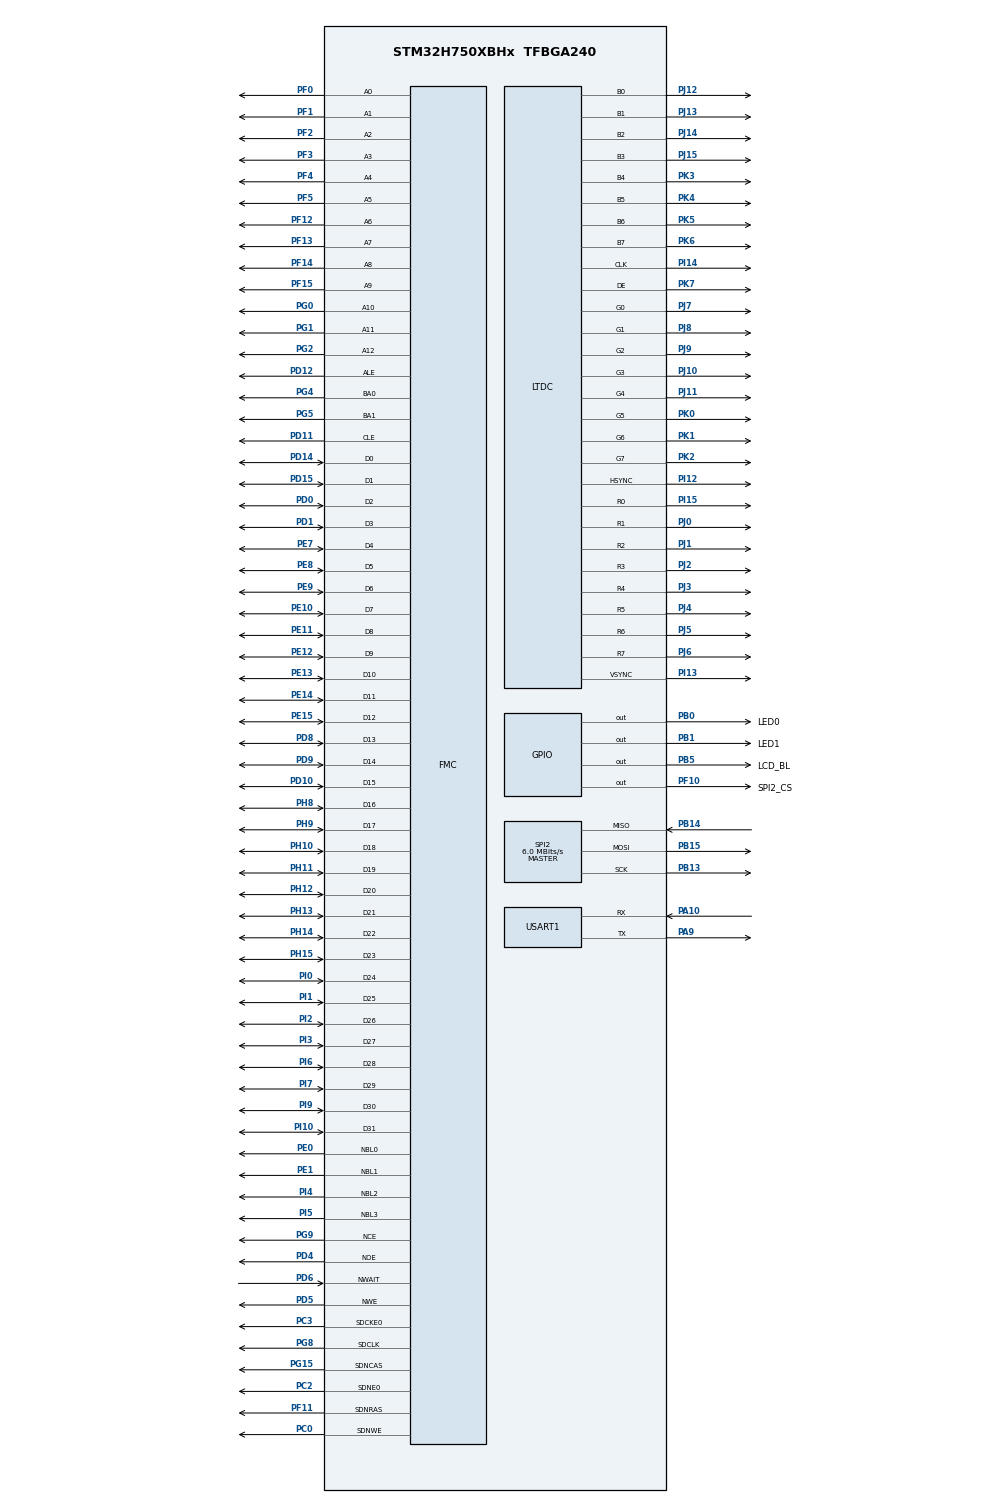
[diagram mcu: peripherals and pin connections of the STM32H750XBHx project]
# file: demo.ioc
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CORTEX_M7.CPU_DCache=Enabled
CORTEX_M7.CPU_ICache=Enabled
Dma.Request0=USART1_RX
Dma.Request1=USART1_TX
Dma.USART1_RX.0.Direction=DMA_PERIPH_TO_MEMORY
Dma.USART1_RX.0.EventEnable=DISABLE
Dma.USART1_RX.0.FIFOMode=DMA_FIFOMODE_DISABLE
Dma.USART1_RX.0.Instance=DMA1_Stream0
Dma.USART1_RX.0.MemDataAlignment=DMA_MDATAALIGN_BYTE
Dma.USART1_RX.0.MemInc=DMA_MINC_ENABLE
Dma.USART1_RX.0.Mode=DMA_CIRCULAR
Dma.USART1_RX.0.PeriphDataAlignment=DMA_PDATAALIGN_BYTE
Dma.USART1_RX.0.PeriphInc=DMA_PINC_DISABLE
Dma.USART1_RX.0.Polarity=HAL_DMAMUX_REQ_GEN_RISING
Dma.USART1_RX.0.Priority=DMA_PRIORITY_HIGH
Dma.USART1_RX.0.RequestNumber=1
Dma.USART1_RX.0.SignalID=NONE
Dma.USART1_RX.0.SyncEnable=DISABLE
Dma.USART1_RX.0.SyncPolarity=HAL_DMAMUX_SYNC_NO_EVENT
Dma.USART1_RX.0.SyncRequestNumber=1
Dma.USART1_RX.0.SyncSignalID=NONE
Dma.USART1_TX.1.Direction=DMA_MEMORY_TO_PERIPH
Dma.USART1_TX.1.EventEnable=DISABLE
Dma.USART1_TX.1.FIFOMode=DMA_FIFOMODE_DISABLE
Dma.USART1_TX.1.Instance=DMA1_Stream1
Dma.USART1_TX.1.MemDataAlignment=DMA_MDATAALIGN_BYTE
Dma.USART1_TX.1.MemInc=DMA_MINC_ENABLE
Dma.USART1_TX.1.Mode=DMA_CIRCULAR
Dma.USART1_TX.1.PeriphDataAlignment=DMA_PDATAALIGN_BYTE
Dma.USART1_TX.1.PeriphInc=DMA_PINC_DISABLE
Dma.USART1_TX.1.Polarity=HAL_DMAMUX_REQ_GEN_RISING
Dma.USART1_TX.1.Priority=DMA_PRIORITY_HIGH
Dma.USART1_TX.1.RequestNumber=1
Dma.USART1_TX.1.SignalID=NONE
Dma.USART1_TX.1.SyncEnable=DISABLE
Dma.USART1_TX.1.SyncPolarity=HAL_DMAMUX_SYNC_NO_EVENT
Dma.USART1_TX.1.SyncRequestNumber=1
Dma.USART1_TX.1.SyncSignalID=NONE
FMC.AttributeSpaceHiZSetupTime1=10
FMC.AttributeSpaceHoldSetupTime1=10
FMC.AttributeSpaceSetupTime1=10
FMC.AttributeSpaceWaitSetupTime1=10
FMC.CASLatency1=FMC_SDRAM_CAS_LATENCY_2
FMC.ColumnBitsNumber1=FMC_SDRAM_COLUMN_BITS_NUM_9
FMC.CommonSpaceHiZSetupTime1=10
FMC.CommonSpaceHoldSetupTime1=10
FMC.CommonSpaceSetupTime1=10
FMC.CommonSpaceWaitSetupTime1=10
FMC.ECCPageSize1=FMC_NAND_ECC_PAGE_SIZE_512BYTE
FMC.ExitSelfRefreshDelay1=8
FMC.LoadToActiveDelay1=2
FMC.NandPageSize1=0
FMC.RCDDelay1=2
FMC.RPDelay1=2
FMC.ReadBurst1=FMC_SDRAM_RBURST_ENABLE
FMC.RowCycleDelay1=6
FMC.SDClockPeriod1=FMC_SDRAM_CLOCK_PERIOD_2
FMC.SelfRefreshTime1=6
FMC.TARSetupTime1=10
FMC.TCLRSetupTime1=10
FMC.WriteRecoveryTime1=4
LTDC.ActiveH=1024
LTDC.ActiveW=600
Mcu.Family=STM32H7
Mcu.Name=STM32H750XBHx
Mcu.Package=TFBGA240
NVIC.DMA1_Stream0_IRQn=true\:0\:0\:false\:false\:true\:false\:true\:true
NVIC.DMA1_Stream1_IRQn=true\:0\:0\:false\:false\:true\:false\:true\:true
NVIC.FMC_IRQn=true\:0\:0\:false\:false\:true\:true\:true\:true
NVIC.PriorityGroup=NVIC_PRIORITYGROUP_4
PA10.Mode=Asynchronous
PA10.Signal=USART1_RX
PA13\ (JTMS/SWDIO).Mode=Serial_Wire
PA13\ (JTMS/SWDIO).Signal=DEBUG_JTMS-SWDIO
PA14\ (JTCK/SWCLK).Mode=Serial_Wire
PA14\ (JTCK/SWCLK).Signal=DEBUG_JTCK-SWCLK
PA9.Mode=Asynchronous
PA9.Signal=USART1_TX
PB0.GPIO_Label=LED0
PB0.GPIO_ModeDefaultOutputPP=GPIO_MODE_OUTPUT_PP
PB0.GPIO_PuPd=GPIO_PULLDOWN
PB0.GPIO_Speed=GPIO_SPEED_FREQ_MEDIUM
PB0.PinState=GPIO_PIN_RESET
PB0.Signal=GPIO_Output
PB1.GPIO_Label=LED1
PB1.GPIO_ModeDefaultOutputPP=GPIO_MODE_OUTPUT_PP
PB1.GPIO_PuPd=GPIO_PULLDOWN
PB1.GPIO_Speed=GPIO_SPEED_FREQ_MEDIUM
PB1.PinState=GPIO_PIN_RESET
PB1.Signal=GPIO_Output
PB13.Mode=Full_Duplex_Master
PB13.Signal=SPI2_SCK
PB14.Mode=Full_Duplex_Master
PB14.Signal=SPI2_MISO
PB15.Mode=Full_Duplex_Master
PB15.Signal=SPI2_MOSI
PB5.GPIO_Label=LCD_BL
PB5.GPIO_PuPd=GPIO_PULLUP
PB5.GPIO_Speed=GPIO_SPEED_FREQ_HIGH
PB5.Signal=GPIO_Output
PC0.GPIO_Mode=GPIO_MODE_AF_PP
PC0.GPIO_PuPd=GPIO_PULLUP
PC0.GPIO_Speed_High_Default=GPIO_SPEED_FREQ_VERY_HIGH
PC0.Signal=FMC_SDNWE
PC14-OSC32_IN\ (OSC32_IN).Mode=LSE-External-Oscillator
PC14-OSC32_IN\ (OSC32_IN).Signal=RCC_OSC32_IN
PC15-OSC32_OUT\ (OSC32_OUT).Mode=LSE-External-Oscillator
PC15-OSC32_OUT\ (OSC32_OUT).Signal=RCC_OSC32_OUT
PC2.GPIO_Mode=GPIO_MODE_AF_PP
PC2.GPIO_PuPd=GPIO_PULLUP
PC2.GPIO_Speed_High_Default=GPIO_SPEED_FREQ_VERY_HIGH
PC2.Mode=SdramChipSelect1_1
PC2.Signal=FMC_SDNE0
PC3.GPIO_Mode=GPIO_MODE_AF_PP
PC3.GPIO_PuPd=GPIO_PULLUP
PC3.GPIO_Speed_High_Default=GPIO_SPEED_FREQ_VERY_HIGH
PC3.Mode=SdramChipSelect1_1
PC3.Signal=FMC_SDCKE0
PD0.GPIO_Mode=GPIO_MODE_AF_PP
PD0.GPIO_PuPd=GPIO_PULLUP
PD0.GPIO_Speed_High_Default=GPIO_SPEED_FREQ_VERY_HIGH
PD0.Signal=FMC_D2_DA2
PD1.GPIO_Mode=GPIO_MODE_AF_PP
PD1.GPIO_PuPd=GPIO_PULLUP
PD1.GPIO_Speed_High_Default=GPIO_SPEED_FREQ_VERY_HIGH
PD1.Signal=FMC_D3_DA3
PD10.GPIO_Mode=GPIO_MODE_AF_PP
PD10.GPIO_PuPd=GPIO_PULLUP
PD10.GPIO_Speed_High_Default=GPIO_SPEED_FREQ_VERY_HIGH
PD10.Signal=FMC_D15_DA15
PD11.GPIO_Mode=GPIO_MODE_AF_PP
PD11.GPIO_PuPd=GPIO_PULLUP
PD11.GPIO_Speed_High_Default=GPIO_SPEED_FREQ_VERY_HIGH
PD11.Signal=FMC_A16_CLE
PD12.GPIO_Mode=GPIO_MODE_AF_PP
PD12.GPIO_PuPd=GPIO_PULLUP
PD12.GPIO_Speed_High_Default=GPIO_SPEED_FREQ_VERY_HIGH
PD12.Signal=FMC_A17_ALE
PD14.GPIO_Mode=GPIO_MODE_AF_PP
PD14.GPIO_PuPd=GPIO_PULLUP
PD14.GPIO_Speed_High_Default=GPIO_SPEED_FREQ_VERY_HIGH
PD14.Signal=FMC_D0_DA0
PD15.GPIO_Mode=GPIO_MODE_AF_PP
PD15.GPIO_PuPd=GPIO_PULLUP
PD15.GPIO_Speed_High_Default=GPIO_SPEED_FREQ_VERY_HIGH
PD15.Signal=FMC_D1_DA1
PD4.GPIO_Mode=GPIO_MODE_AF_PP
PD4.GPIO_PuPd=GPIO_PULLUP
PD4.GPIO_Speed_High_Default=GPIO_SPEED_FREQ_VERY_HIGH
PD4.Signal=FMC_NOE
PD5.GPIO_Mode=GPIO_MODE_AF_PP
PD5.GPIO_PuPd=GPIO_PULLUP
PD5.GPIO_Speed_High_Default=GPIO_SPEED_FREQ_VERY_HIGH
PD5.Signal=FMC_NWE
PD6.GPIO_Mode=GPIO_MODE_AF_PP
PD6.GPIO_PuPd=GPIO_PULLUP
PD6.GPIO_Speed_High_Default=GPIO_SPEED_FREQ_VERY_HIGH
PD6.Signal=FMC_NWAIT
PD8.GPIO_Mode=GPIO_MODE_AF_PP
PD8.GPIO_PuPd=GPIO_PULLUP
PD8.GPIO_Speed_High_Default=GPIO_SPEED_FREQ_VERY_HIGH
PD8.Signal=FMC_D13_DA13
PD9.GPIO_Mode=GPIO_MODE_AF_PP
PD9.GPIO_PuPd=GPIO_PULLUP
PD9.GPIO_Speed_High_Default=GPIO_SPEED_FREQ_VERY_HIGH
PD9.Signal=FMC_D14_DA14
PE0.GPIO_Mode=GPIO_MODE_AF_PP
PE0.GPIO_PuPd=GPIO_PULLUP
PE0.GPIO_Speed_High_Default=GPIO_SPEED_FREQ_VERY_HIGH
PE0.Signal=FMC_NBL0
PE1.GPIO_Mode=GPIO_MODE_AF_PP
PE1.GPIO_PuPd=GPIO_PULLUP
PE1.GPIO_Speed_High_Default=GPIO_SPEED_FREQ_VERY_HIGH
PE1.Signal=FMC_NBL1
PE10.GPIO_Mode=GPIO_MODE_AF_PP
PE10.GPIO_PuPd=GPIO_PULLUP
PE10.GPIO_Speed_High_Default=GPIO_SPEED_FREQ_VERY_HIGH
PE10.Signal=FMC_D7_DA7
PE11.GPIO_Mode=GPIO_MODE_AF_PP
PE11.GPIO_PuPd=GPIO_PULLUP
PE11.GPIO_Speed_High_Default=GPIO_SPEED_FREQ_VERY_HIGH
PE11.Signal=FMC_D8_DA8
PE12.GPIO_Mode=GPIO_MODE_AF_PP
PE12.GPIO_PuPd=GPIO_PULLUP
PE12.GPIO_Speed_High_Default=GPIO_SPEED_FREQ_VERY_HIGH
PE12.Signal=FMC_D9_DA9
PE13.GPIO_Mode=GPIO_MODE_AF_PP
PE13.GPIO_PuPd=GPIO_PULLUP
PE13.GPIO_Speed_High_Default=GPIO_SPEED_FREQ_VERY_HIGH
PE13.Signal=FMC_D10_DA10
PE14.GPIO_Mode=GPIO_MODE_AF_PP
PE14.GPIO_PuPd=GPIO_PULLUP
PE14.GPIO_Speed_High_Default=GPIO_SPEED_FREQ_VERY_HIGH
PE14.Signal=FMC_D11_DA11
PE15.GPIO_Mode=GPIO_MODE_AF_PP
PE15.GPIO_PuPd=GPIO_PULLUP
PE15.GPIO_Speed_High_Default=GPIO_SPEED_FREQ_VERY_HIGH
PE15.Signal=FMC_D12_DA12
PE7.GPIO_Mode=GPIO_MODE_AF_PP
PE7.GPIO_PuPd=GPIO_PULLUP
PE7.GPIO_Speed_High_Default=GPIO_SPEED_FREQ_VERY_HIGH
PE7.Signal=FMC_D4_DA4
PE8.GPIO_Mode=GPIO_MODE_AF_PP
PE8.GPIO_PuPd=GPIO_PULLUP
PE8.GPIO_Speed_High_Default=GPIO_SPEED_FREQ_VERY_HIGH
PE8.Signal=FMC_D5_DA5
PE9.GPIO_Mode=GPIO_MODE_AF_PP
PE9.GPIO_PuPd=GPIO_PULLUP
PE9.GPIO_Speed_High_Default=GPIO_SPEED_FREQ_VERY_HIGH
PE9.Signal=FMC_D6_DA6
PF0.GPIO_Mode=GPIO_MODE_AF_PP
PF0.GPIO_PuPd=GPIO_PULLUP
PF0.GPIO_Speed_High_Default=GPIO_SPEED_FREQ_VERY_HIGH
PF0.Signal=FMC_A0
PF1.GPIO_Mode=GPIO_MODE_AF_PP
PF1.GPIO_PuPd=GPIO_PULLUP
PF1.GPIO_Speed_High_Default=GPIO_SPEED_FREQ_VERY_HIGH
PF1.Signal=FMC_A1
PF10.GPIO_Label=SPI2_CS
PF10.GPIO_ModeDefaultOutputPP=GPIO_MODE_OUTPUT_PP
PF10.GPIO_PuPd=GPIO_PULLUP
PF10.GPIO_Speed=GPIO_SPEED_FREQ_MEDIUM
PF10.PinState=GPIO_PIN_SET
PF10.Signal=GPIO_Output
PF11.GPIO_Mode=GPIO_MODE_AF_PP
PF11.GPIO_PuPd=GPIO_PULLUP
PF11.GPIO_Speed_High_Default=GPIO_SPEED_FREQ_VERY_HIGH
PF11.Signal=FMC_SDNRAS
PF12.GPIO_Mode=GPIO_MODE_AF_PP
PF12.GPIO_PuPd=GPIO_PULLUP
PF12.GPIO_Speed_High_Default=GPIO_SPEED_FREQ_VERY_HIGH
PF12.Signal=FMC_A6
PF13.GPIO_Mode=GPIO_MODE_AF_PP
PF13.GPIO_PuPd=GPIO_PULLUP
PF13.GPIO_Speed_High_Default=GPIO_SPEED_FREQ_VERY_HIGH
PF13.Signal=FMC_A7
PF14.GPIO_Mode=GPIO_MODE_AF_PP
PF14.GPIO_PuPd=GPIO_PULLUP
PF14.GPIO_Speed_High_Default=GPIO_SPEED_FREQ_VERY_HIGH
PF14.Signal=FMC_A8
PF15.GPIO_Mode=GPIO_MODE_AF_PP
PF15.GPIO_PuPd=GPIO_PULLUP
PF15.GPIO_Speed_High_Default=GPIO_SPEED_FREQ_VERY_HIGH
PF15.Signal=FMC_A9
PF2.GPIO_Mode=GPIO_MODE_AF_PP
PF2.GPIO_PuPd=GPIO_PULLUP
PF2.GPIO_Speed_High_Default=GPIO_SPEED_FREQ_VERY_HIGH
PF2.Signal=FMC_A2
PF3.GPIO_Mode=GPIO_MODE_AF_PP
PF3.GPIO_PuPd=GPIO_PULLUP
PF3.GPIO_Speed_High_Default=GPIO_SPEED_FREQ_VERY_HIGH
PF3.Signal=FMC_A3
PF4.GPIO_Mode=GPIO_MODE_AF_PP
PF4.GPIO_PuPd=GPIO_PULLUP
PF4.GPIO_Speed_High_Default=GPIO_SPEED_FREQ_VERY_HIGH
PF4.Signal=FMC_A4
PF5.GPIO_Mode=GPIO_MODE_AF_PP
PF5.GPIO_PuPd=GPIO_PULLUP
PF5.GPIO_Speed_High_Default=GPIO_SPEED_FREQ_VERY_HIGH
PF5.Signal=FMC_A5
PG0.GPIO_Mode=GPIO_MODE_AF_PP
PG0.GPIO_PuPd=GPIO_PULLUP
PG0.GPIO_Speed_High_Default=GPIO_SPEED_FREQ_VERY_HIGH
PG0.Signal=FMC_A10
PG1.GPIO_Mode=GPIO_MODE_AF_PP
PG1.GPIO_PuPd=GPIO_PULLUP
PG1.GPIO_Speed_High_Default=GPIO_SPEED_FREQ_VERY_HIGH
PG1.Signal=FMC_A11
PG15.GPIO_Mode=GPIO_MODE_AF_PP
PG15.GPIO_PuPd=GPIO_PULLUP
PG15.GPIO_Speed_High_Default=GPIO_SPEED_FREQ_VERY_HIGH
PG15.Signal=FMC_SDNCAS
PG2.GPIO_Mode=GPIO_MODE_AF_PP
PG2.GPIO_PuPd=GPIO_PULLUP
PG2.GPIO_Speed_High_Default=GPIO_SPEED_FREQ_VERY_HIGH
PG2.Signal=FMC_A12
PG4.GPIO_Mode=GPIO_MODE_AF_PP
PG4.GPIO_PuPd=GPIO_PULLUP
PG4.GPIO_Speed_High_Default=GPIO_SPEED_FREQ_VERY_HIGH
PG4.Signal=FMC_A14_BA0
PG5.GPIO_Mode=GPIO_MODE_AF_PP
PG5.GPIO_PuPd=GPIO_PULLUP
PG5.GPIO_Speed_High_Default=GPIO_SPEED_FREQ_VERY_HIGH
PG5.Signal=FMC_A15_BA1
PG8.GPIO_Mode=GPIO_MODE_AF_PP
PG8.GPIO_PuPd=GPIO_PULLUP
PG8.GPIO_Speed_High_Default=GPIO_SPEED_FREQ_VERY_HIGH
PG8.Signal=FMC_SDCLK
PG9.GPIO_Mode=GPIO_MODE_AF_PP
PG9.GPIO_PuPd=GPIO_PULLUP
PG9.GPIO_Speed_High_Default=GPIO_SPEED_FREQ_VERY_HIGH
PG9.Mode=NandChipSelect3_1
PG9.Signal=FMC_NCE
PH0-OSC_IN\ (PH0).Mode=HSE-External-Oscillator
PH0-OSC_IN\ (PH0).Signal=RCC_OSC_IN
PH1-OSC_OUT\ (PH1).Mode=HSE-External-Oscillator
PH1-OSC_OUT\ (PH1).Signal=RCC_OSC_OUT
PH10.GPIO_Mode=GPIO_MODE_AF_PP
PH10.GPIO_PuPd=GPIO_PULLUP
PH10.GPIO_Speed_High_Default=GPIO_SPEED_FREQ_VERY_HIGH
PH10.Signal=FMC_D18
PH11.GPIO_Mode=GPIO_MODE_AF_PP
PH11.GPIO_PuPd=GPIO_PULLUP
PH11.GPIO_Speed_High_Default=GPIO_SPEED_FREQ_VERY_HIGH
PH11.Signal=FMC_D19
PH12.GPIO_Mode=GPIO_MODE_AF_PP
PH12.GPIO_PuPd=GPIO_PULLUP
PH12.GPIO_Speed_High_Default=GPIO_SPEED_FREQ_VERY_HIGH
PH12.Signal=FMC_D20
PH13.GPIO_Mode=GPIO_MODE_AF_PP
PH13.GPIO_PuPd=GPIO_PULLUP
PH13.GPIO_Speed_High_Default=GPIO_SPEED_FREQ_VERY_HIGH
PH13.Signal=FMC_D21
PH14.GPIO_Mode=GPIO_MODE_AF_PP
PH14.GPIO_PuPd=GPIO_PULLUP
PH14.GPIO_Speed_High_Default=GPIO_SPEED_FREQ_VERY_HIGH
PH14.Signal=FMC_D22
PH15.GPIO_Mode=GPIO_MODE_AF_PP
PH15.GPIO_PuPd=GPIO_PULLUP
PH15.GPIO_Speed_High_Default=GPIO_SPEED_FREQ_VERY_HIGH
PH15.Signal=FMC_D23
PH8.GPIO_Mode=GPIO_MODE_AF_PP
PH8.GPIO_PuPd=GPIO_PULLUP
PH8.GPIO_Speed_High_Default=GPIO_SPEED_FREQ_VERY_HIGH
PH8.Signal=FMC_D16
PH9.GPIO_Mode=GPIO_MODE_AF_PP
PH9.GPIO_PuPd=GPIO_PULLUP
PH9.GPIO_Speed_High_Default=GPIO_SPEED_FREQ_VERY_HIGH
PH9.Signal=FMC_D17
PI0.GPIO_Mode=GPIO_MODE_AF_PP
PI0.GPIO_PuPd=GPIO_PULLUP
PI0.GPIO_Speed_High_Default=GPIO_SPEED_FREQ_VERY_HIGH
PI0.Signal=FMC_D24
PI1.GPIO_Mode=GPIO_MODE_AF_PP
PI1.GPIO_PuPd=GPIO_PULLUP
PI1.GPIO_Speed_High_Default=GPIO_SPEED_FREQ_VERY_HIGH
PI1.Signal=FMC_D25
PI10.GPIO_Mode=GPIO_MODE_AF_PP
PI10.GPIO_PuPd=GPIO_PULLUP
PI10.GPIO_Speed_High_Default=GPIO_SPEED_FREQ_VERY_HIGH
PI10.Signal=FMC_D31
PI12.GPIO_Mode=GPIO_MODE_AF_PP
PI12.GPIO_PuPd=GPIO_NOPULL
PI12.GPIO_Speed=GPIO_SPEED_FREQ_VERY_HIGH
PI12.Mode=RGB888
PI12.Signal=LTDC_HSYNC
PI13.GPIO_Mode=GPIO_MODE_AF_PP
PI13.GPIO_PuPd=GPIO_NOPULL
PI13.GPIO_Speed=GPIO_SPEED_FREQ_VERY_HIGH
PI13.Mode=RGB888
PI13.Signal=LTDC_VSYNC
PI14.GPIO_Mode=GPIO_MODE_AF_PP
PI14.GPIO_PuPd=GPIO_NOPULL
PI14.GPIO_Speed=GPIO_SPEED_FREQ_VERY_HIGH
PI14.Mode=RGB888
PI14.Signal=LTDC_CLK
PI15.GPIO_Mode=GPIO_MODE_AF_PP
PI15.GPIO_PuPd=GPIO_NOPULL
PI15.GPIO_Speed=GPIO_SPEED_FREQ_VERY_HIGH
PI15.Mode=RGB888
PI15.Signal=LTDC_R0
PI2.GPIO_Mode=GPIO_MODE_AF_PP
PI2.GPIO_PuPd=GPIO_PULLUP
PI2.GPIO_Speed_High_Default=GPIO_SPEED_FREQ_VERY_HIGH
PI2.Signal=FMC_D26
PI3.GPIO_Mode=GPIO_MODE_AF_PP
PI3.GPIO_PuPd=GPIO_PULLUP
PI3.GPIO_Speed_High_Default=GPIO_SPEED_FREQ_VERY_HIGH
PI3.Signal=FMC_D27
PI4.GPIO_Mode=GPIO_MODE_AF_PP
PI4.GPIO_PuPd=GPIO_PULLUP
PI4.GPIO_Speed_High_Default=GPIO_SPEED_FREQ_VERY_HIGH
PI4.Signal=FMC_NBL2
PI5.GPIO_Mode=GPIO_MODE_AF_PP
PI5.GPIO_PuPd=GPIO_PULLUP
PI5.GPIO_Speed_High_Default=GPIO_SPEED_FREQ_VERY_HIGH
PI5.Signal=FMC_NBL3
PI6.GPIO_Mode=GPIO_MODE_AF_PP
PI6.GPIO_PuPd=GPIO_PULLUP
PI6.GPIO_Speed_High_Default=GPIO_SPEED_FREQ_VERY_HIGH
PI6.Signal=FMC_D28
PI7.GPIO_Mode=GPIO_MODE_AF_PP
PI7.GPIO_PuPd=GPIO_PULLUP
PI7.GPIO_Speed_High_Default=GPIO_SPEED_FREQ_VERY_HIGH
PI7.Signal=FMC_D29
PI9.GPIO_Mode=GPIO_MODE_AF_PP
PI9.GPIO_PuPd=GPIO_PULLUP
PI9.GPIO_Speed_High_Default=GPIO_SPEED_FREQ_VERY_HIGH
PI9.Signal=FMC_D30
PJ0.GPIO_Mode=GPIO_MODE_AF_PP
PJ0.GPIO_PuPd=GPIO_NOPULL
PJ0.GPIO_Speed=GPIO_SPEED_FREQ_VERY_HIGH
PJ0.Mode=RGB888
PJ0.Signal=LTDC_R1
PJ1.GPIO_Mode=GPIO_MODE_AF_PP
PJ1.GPIO_PuPd=GPIO_NOPULL
PJ1.GPIO_Speed=GPIO_SPEED_FREQ_VERY_HIGH
PJ1.Mode=RGB888
PJ1.Signal=LTDC_R2
PJ10.GPIO_Mode=GPIO_MODE_AF_PP
PJ10.GPIO_PuPd=GPIO_NOPULL
PJ10.GPIO_Speed=GPIO_SPEED_FREQ_VERY_HIGH
PJ10.Mode=RGB888
PJ10.Signal=LTDC_G3
PJ11.GPIO_Mode=GPIO_MODE_AF_PP
PJ11.GPIO_PuPd=GPIO_NOPULL
PJ11.GPIO_Speed=GPIO_SPEED_FREQ_VERY_HIGH
PJ11.Mode=RGB888
PJ11.Signal=LTDC_G4
PJ12.GPIO_Mode=GPIO_MODE_AF_PP
PJ12.GPIO_PuPd=GPIO_NOPULL
PJ12.GPIO_Speed=GPIO_SPEED_FREQ_VERY_HIGH
PJ12.Mode=RGB888
PJ12.Signal=LTDC_B0
PJ13.GPIO_Mode=GPIO_MODE_AF_PP
PJ13.GPIO_PuPd=GPIO_NOPULL
PJ13.GPIO_Speed=GPIO_SPEED_FREQ_VERY_HIGH
PJ13.Mode=RGB888
PJ13.Signal=LTDC_B1
PJ14.GPIO_Mode=GPIO_MODE_AF_PP
PJ14.GPIO_PuPd=GPIO_NOPULL
PJ14.GPIO_Speed=GPIO_SPEED_FREQ_VERY_HIGH
PJ14.Mode=RGB888
PJ14.Signal=LTDC_B2
PJ15.GPIO_Mode=GPIO_MODE_AF_PP
PJ15.GPIO_PuPd=GPIO_NOPULL
PJ15.GPIO_Speed=GPIO_SPEED_FREQ_VERY_HIGH
PJ15.Mode=RGB888
PJ15.Signal=LTDC_B3
PJ2.GPIO_Mode=GPIO_MODE_AF_PP
PJ2.GPIO_PuPd=GPIO_NOPULL
PJ2.GPIO_Speed=GPIO_SPEED_FREQ_VERY_HIGH
PJ2.Mode=RGB888
PJ2.Signal=LTDC_R3
PJ3.GPIO_Mode=GPIO_MODE_AF_PP
PJ3.GPIO_PuPd=GPIO_NOPULL
PJ3.GPIO_Speed=GPIO_SPEED_FREQ_VERY_HIGH
PJ3.Mode=RGB888
PJ3.Signal=LTDC_R4
PJ4.GPIO_Mode=GPIO_MODE_AF_PP
PJ4.GPIO_PuPd=GPIO_NOPULL
PJ4.GPIO_Speed=GPIO_SPEED_FREQ_VERY_HIGH
PJ4.Mode=RGB888
PJ4.Signal=LTDC_R5
PJ5.GPIO_Mode=GPIO_MODE_AF_PP
PJ5.GPIO_PuPd=GPIO_NOPULL
PJ5.GPIO_Speed=GPIO_SPEED_FREQ_VERY_HIGH
PJ5.Mode=RGB888
PJ5.Signal=LTDC_R6
PJ6.GPIO_Mode=GPIO_MODE_AF_PP
PJ6.GPIO_PuPd=GPIO_NOPULL
PJ6.GPIO_Speed=GPIO_SPEED_FREQ_VERY_HIGH
PJ6.Mode=RGB888
PJ6.Signal=LTDC_R7
PJ7.GPIO_Mode=GPIO_MODE_AF_PP
PJ7.GPIO_PuPd=GPIO_NOPULL
PJ7.GPIO_Speed=GPIO_SPEED_FREQ_VERY_HIGH
PJ7.Mode=RGB888
PJ7.Signal=LTDC_G0
PJ8.GPIO_Mode=GPIO_MODE_AF_PP
PJ8.GPIO_PuPd=GPIO_NOPULL
PJ8.GPIO_Speed=GPIO_SPEED_FREQ_VERY_HIGH
PJ8.Mode=RGB888
PJ8.Signal=LTDC_G1
PJ9.GPIO_Mode=GPIO_MODE_AF_PP
PJ9.GPIO_PuPd=GPIO_NOPULL
PJ9.GPIO_Speed=GPIO_SPEED_FREQ_VERY_HIGH
PJ9.Mode=RGB888
PJ9.Signal=LTDC_G2
PK0.GPIO_Mode=GPIO_MODE_AF_PP
PK0.GPIO_PuPd=GPIO_NOPULL
PK0.GPIO_Speed=GPIO_SPEED_FREQ_VERY_HIGH
PK0.Mode=RGB888
PK0.Signal=LTDC_G5
PK1.GPIO_Mode=GPIO_MODE_AF_PP
PK1.GPIO_PuPd=GPIO_NOPULL
PK1.GPIO_Speed=GPIO_SPEED_FREQ_VERY_HIGH
PK1.Mode=RGB888
PK1.Signal=LTDC_G6
PK2.GPIO_Mode=GPIO_MODE_AF_PP
PK2.GPIO_PuPd=GPIO_NOPULL
PK2.GPIO_Speed=GPIO_SPEED_FREQ_VERY_HIGH
PK2.Mode=RGB888
PK2.Signal=LTDC_G7
PK3.GPIO_Mode=GPIO_MODE_AF_PP
PK3.GPIO_PuPd=GPIO_NOPULL
PK3.GPIO_Speed=GPIO_SPEED_FREQ_VERY_HIGH
PK3.Mode=RGB888
PK3.Signal=LTDC_B4
PK4.GPIO_Mode=GPIO_MODE_AF_PP
PK4.GPIO_PuPd=GPIO_NOPULL
PK4.GPIO_Speed=GPIO_SPEED_FREQ_VERY_HIGH
PK4.Mode=RGB888
PK4.Signal=LTDC_B5
PK5.GPIO_Mode=GPIO_MODE_AF_PP
PK5.GPIO_PuPd=GPIO_NOPULL
PK5.GPIO_Speed=GPIO_SPEED_FREQ_VERY_HIGH
PK5.Mode=RGB888
PK5.Signal=LTDC_B6
PK6.GPIO_Mode=GPIO_MODE_AF_PP
PK6.GPIO_PuPd=GPIO_NOPULL
PK6.GPIO_Speed=GPIO_SPEED_FREQ_VERY_HIGH
PK6.Mode=RGB888
PK6.Signal=LTDC_B7
PK7.GPIO_Mode=GPIO_MODE_AF_PP
PK7.GPIO_PuPd=GPIO_NOPULL
PK7.GPIO_Speed=GPIO_SPEED_FREQ_VERY_HIGH
PK7.Mode=RGB888
PK7.Signal=LTDC_DE
ProjectManager.HeapSize=0x200
ProjectManager.StackSize=0x400
ProjectManager.TargetToolchain=MDK-ARM V5.32
RCC.ADCFreq_Value=60000000
RCC.APB1Freq_Value=120000000
RCC.APB2Freq_Value=120000000
RCC.APB3Freq_Value=120000000
RCC.APB4Freq_Value=120000000
RCC.CortexFreq_Value=480000000
RCC.D1PPRE=RCC_APB3_DIV2
RCC.D2PPRE1=RCC_APB1_DIV2
RCC.D2PPRE2=RCC_APB2_DIV2
RCC.D3PPRE=RCC_APB4_DIV2
RCC.DIVM1=5
RCC.DIVM2=25
RCC.DIVM3=25
RCC.DIVN1=192
RCC.DIVN2=120
RCC.DIVN3=240
RCC.DIVQ1=20
RCC.EnbaleCSS=true
RCC.FMCCLockSelection=RCC_FMCCLKSOURCE_PLL
RCC.HCLKFreq_Value=240000000
RCC.HPRE=RCC_HCLK_DIV2
RCC.PLLSourceVirtual=RCC_PLLSOURCE_HSE
RCC.SYSCLKFreq_VALUE=480000000
RCC.SYSCLKSource=RCC_SYSCLKSOURCE_PLLCLK
RCC.USBFreq_Value=48000000
SH.FMC_A0.0=FMC_A0,13b-sda1
SH.FMC_A1.0=FMC_A1,13b-sda1
SH.FMC_A10.0=FMC_A10,13b-sda1
SH.FMC_A11.0=FMC_A11,13b-sda1
SH.FMC_A12.0=FMC_A12,13b-sda1
SH.FMC_A14_BA0.0=FMC_BA0,FourSdramBanks1
SH.FMC_A15_BA1.0=FMC_BA1,FourSdramBanks1
SH.FMC_A16_CLE.0=FMC_CLE,8b-dmux1
SH.FMC_A17_ALE.0=FMC_ALE,8b-dmux1
SH.FMC_A2.0=FMC_A2,13b-sda1
SH.FMC_A3.0=FMC_A3,13b-sda1
SH.FMC_A4.0=FMC_A4,13b-sda1
SH.FMC_A5.0=FMC_A5,13b-sda1
SH.FMC_A6.0=FMC_A6,13b-sda1
SH.FMC_A7.0=FMC_A7,13b-sda1
SH.FMC_A8.0=FMC_A8,13b-sda1
SH.FMC_A9.0=FMC_A9,13b-sda1
SH.FMC_D0_DA0.0=FMC_D0,sd-32b-d1
SH.FMC_D0_DA0.1=FMC_D0,8b-dmux1
SH.FMC_D10_DA10.0=FMC_D10,sd-32b-d1
SH.FMC_D11_DA11.0=FMC_D11,sd-32b-d1
SH.FMC_D12_DA12.0=FMC_D12,sd-32b-d1
SH.FMC_D13_DA13.0=FMC_D13,sd-32b-d1
SH.FMC_D14_DA14.0=FMC_D14,sd-32b-d1
SH.FMC_D15_DA15.0=FMC_D15,sd-32b-d1
SH.FMC_D16.0=FMC_D16,sd-32b-d1
SH.FMC_D17.0=FMC_D17,sd-32b-d1
SH.FMC_D18.0=FMC_D18,sd-32b-d1
SH.FMC_D19.0=FMC_D19,sd-32b-d1
SH.FMC_D1_DA1.0=FMC_D1,sd-32b-d1
SH.FMC_D1_DA1.1=FMC_D1,8b-dmux1
SH.FMC_D20.0=FMC_D20,sd-32b-d1
SH.FMC_D21.0=FMC_D21,sd-32b-d1
SH.FMC_D22.0=FMC_D22,sd-32b-d1
SH.FMC_D23.0=FMC_D23,sd-32b-d1
SH.FMC_D24.0=FMC_D24,sd-32b-d1
SH.FMC_D25.0=FMC_D25,sd-32b-d1
SH.FMC_D26.0=FMC_D26,sd-32b-d1
SH.FMC_D27.0=FMC_D27,sd-32b-d1
SH.FMC_D28.0=FMC_D28,sd-32b-d1
SH.FMC_D29.0=FMC_D29,sd-32b-d1
SH.FMC_D2_DA2.0=FMC_D2,sd-32b-d1
SH.FMC_D2_DA2.1=FMC_D2,8b-dmux1
SH.FMC_D30.0=FMC_D30,sd-32b-d1
SH.FMC_D31.0=FMC_D31,sd-32b-d1
SH.FMC_D3_DA3.0=FMC_D3,sd-32b-d1
SH.FMC_D3_DA3.1=FMC_D3,8b-dmux1
SH.FMC_D4_DA4.0=FMC_D4,sd-32b-d1
SH.FMC_D4_DA4.1=FMC_D4,8b-dmux1
SH.FMC_D5_DA5.0=FMC_D5,sd-32b-d1
SH.FMC_D5_DA5.1=FMC_D5,8b-dmux1
SH.FMC_D6_DA6.0=FMC_D6,sd-32b-d1
SH.FMC_D6_DA6.1=FMC_D6,8b-dmux1
SH.FMC_D7_DA7.0=FMC_D7,sd-32b-d1
SH.FMC_D7_DA7.1=FMC_D7,8b-dmux1
SH.FMC_D8_DA8.0=FMC_D8,sd-32b-d1
SH.FMC_D9_DA9.0=FMC_D9,sd-32b-d1
SH.FMC_NBL0.0=FMC_NBL0,Sd4ByteEnable1
SH.FMC_NBL1.0=FMC_NBL1,Sd4ByteEnable1
SH.FMC_NBL2.0=FMC_NBL2,Sd4ByteEnable1
SH.FMC_NBL3.0=FMC_NBL3,Sd4ByteEnable1
SH.FMC_NOE.0=FMC_NOE,8b-dmux1
SH.FMC_NWAIT.0=FMC_NWAIT,Wait1
SH.FMC_NWE.0=FMC_NWE,8b-dmux1
SH.FMC_SDCLK.0=FMC_SDCLK,13b-sda1
SH.FMC_SDNCAS.0=FMC_SDNCAS,13b-sda1
SH.FMC_SDNRAS.0=FMC_SDNRAS,13b-sda1
SH.FMC_SDNWE.0=FMC_SDNWE,13b-sda1
SPI2.BaudRatePrescaler=SPI_BAUDRATEPRESCALER_8
SPI2.CalculateBaudRate=6.0 MBits/s
SPI2.DataSize=SPI_DATASIZE_8BIT
SPI2.Direction=SPI_DIRECTION_2LINES
SPI2.Mode=SPI_MODE_MASTER
SPI2.VirtualType=VM_MASTER
USART1.DMADisableonRxErrorParam=ADVFEATURE_DMA_DISABLEONRXERROR
USART1.VirtualMode-Asynchronous=VM_ASYNC
VP_DMA2D_VS_DMA2D.Mode=DMA2D_Activate
VP_TIM17_VS_ClockSourceINT.Mode=Enable_Timer
board=custom

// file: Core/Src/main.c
/* USER CODE BEGIN Header */
/**
  ******************************************************************************
  * @file           : main.c
  * @brief          : Main program body
  ******************************************************************************
  * @attention
  *
  * Copyright (c) 2023 STMicroelectronics.
  * All rights reserved.
  *
  * This software is licensed under terms that can be found in the LICENSE file
  * in the root directory of this software component.
  * If no LICENSE file comes with this software, it is provided AS-IS.
  *
  ******************************************************************************
  */
/* USER CODE END Header */
#include "main.h"
#include "dma.h"
#include "dma2d.h"
#include "ltdc.h"
#include "spi.h"
#include "tim.h"
#include "usart.h"
#include "gpio.h"
#include "fmc.h"

/* USER CODE BEGIN Includes */
#include <stdio.h>
uint8_t SDRAM_Send_Cmd(uint8_t bankx, uint8_t cmd, uint8_t refresh, uint16_t regval);
/* USER CODE END Includes */

/* USER CODE BEGIN PV */
unsigned char str[] = {"waiting...\r\n"};
unsigned char rec[20];
/* USER CODE END PV */

void SystemClock_Config(void);
void PeriphCommonClock_Config(void);

/* USER CODE BEGIN 0 */
void UART_Init(void)
{
  LL_USART_SetTransferDirection(USART1, LL_USART_DIRECTION_TX_RX);
  // r
  LL_USART_EnableIT_IDLE(USART1);
  LL_DMA_SetMemoryAddress(DMA1, LL_DMA_STREAM_0, (uint32_t)rec);
  LL_DMA_SetDataLength(DMA1, LL_DMA_STREAM_0, 20);
  LL_DMA_SetPeriphAddress(DMA1, LL_DMA_STREAM_0, (uint32_t)&USART1->RDR);
  LL_DMA_EnableIT_TC(DMA1, LL_DMA_STREAM_0);
  LL_DMA_EnableStream(DMA1, LL_DMA_STREAM_0);
  LL_USART_EnableDMAReq_RX(USART1);
  // t
  LL_DMA_SetPeriphAddress(DMA1, LL_DMA_STREAM_1, (uint32_t)&USART1->TDR);
  LL_USART_EnableDMAReq_TX(USART1);
  LL_DMA_EnableIT_TC(DMA1, LL_DMA_STREAM_1);
}

void UART_DMA_Send(USART_TypeDef * USARTx, uint8_t * str, uint16_t size)
{
  LL_DMA_SetMemoryAddress(DMA1, LL_DMA_STREAM_1, (uint32_t)str);
  LL_DMA_SetDataLength(DMA1, LL_DMA_STREAM_1, size);
  LL_DMA_EnableStream(DMA1, LL_DMA_STREAM_1);
}

// uint16_t testsram[250000] __attribute__((section(".ARM.__at_0xC0000000")));
extern SDRAM_HandleTypeDef hsdram1;
#define Bank5_SDRAM_ADDR    ((uint32_t)(0xC0000000)) //SDRAM开始地址
// MAX SIZE 64*1024*1024 = 0x400 0000
// SDRAM配置参数
#define SDRAM_MODEREG_BURST_LENGTH_1             ((uint16_t)0x0000)
#define SDRAM_MODEREG_BURST_LENGTH_2             ((uint16_t)0x0001)
#define SDRAM_MODEREG_BURST_LENGTH_4             ((uint16_t)0x0002)
#define SDRAM_MODEREG_BURST_LENGTH_8             ((uint16_t)0x0004)
#define SDRAM_MODEREG_BURST_TYPE_SEQUENTIAL      ((uint16_t)0x0000)
#define SDRAM_MODEREG_BURST_TYPE_INTERLEAVED     ((uint16_t)0x0008)
#define SDRAM_MODEREG_CAS_LATENCY_2              ((uint16_t)0x0020)
#define SDRAM_MODEREG_CAS_LATENCY_3              ((uint16_t)0x0030)
#define SDRAM_MODEREG_OPERATING_MODE_STANDARD    ((uint16_t)0x0000)
#define SDRAM_MODEREG_WRITEBURST_MODE_PROGRAMMED ((uint16_t)0x0000)
#define SDRAM_MODEREG_WRITEBURST_MODE_SINGLE     ((uint16_t)0x0200)

void SDRAM_Initialization_Sequence(SDRAM_HandleTypeDef * hsdram)
{
  uint32_t temp = 0;
  // SDRAM控制器初始化完成以后还需要按照如下顺序初始化SDRAM
  SDRAM_Send_Cmd(0, FMC_SDRAM_CMD_CLK_ENABLE, 1, 0);       // 时钟配置使能
  HAL_Delay(1);
  SDRAM_Send_Cmd(0, FMC_SDRAM_CMD_PALL, 1, 0);             // 对所有存储区预充电
  SDRAM_Send_Cmd(0, FMC_SDRAM_CMD_AUTOREFRESH_MODE, 8, 0); // 设置自刷新次数
  // 配置模式寄存器,SDRAM的bit0~bit2为指定突发访问的长度，
  // bit3为指定突发访问的类型，bit4~bit6为CAS值，bit7和bit8为运行模式
  // bit9为指定的写突发模式，bit10和bit11位保留位
  temp = (uint32_t)SDRAM_MODEREG_BURST_LENGTH_4          | // 设置突发长度:1(可以是1/2/4/8)
    SDRAM_MODEREG_BURST_TYPE_SEQUENTIAL                  | // 设置突发类型:连续(可以是连续/交错)
    SDRAM_MODEREG_CAS_LATENCY_2                          | // 设置CAS值:2(可以是2/3)
    SDRAM_MODEREG_OPERATING_MODE_STANDARD                | // 设置操作模式:0,标准模式
    SDRAM_MODEREG_WRITEBURST_MODE_SINGLE;                  // 设置突发写模式:1,单点访问
  SDRAM_Send_Cmd(0, FMC_SDRAM_CMD_LOAD_MODE, 1, temp);     // 设置SDRAM的模式寄存器
  // 刷新频率计数器(以SDCLK频率计数),计算方法:
  // COUNT=SDRAM刷新周期/行数-20=SDRAM刷新周期(us)*SDCLK频率(Mhz)/行数
  // 我们使用的SDRAM刷新周期为64ms,SDCLK=200/2=100Mhz,行数为8192(2^13).
  // 所以,COUNT=64*1000*120/8192-20=917.5
  HAL_SDRAM_ProgramRefreshRate(&hsdram1, 917);
}

uint8_t SDRAM_Send_Cmd(uint8_t bankx, uint8_t cmd, uint8_t refresh, uint16_t regval)
{
  uint32_t target_bank = 0;
  FMC_SDRAM_CommandTypeDef Command;

  if (bankx == 0)
  {
    target_bank = FMC_SDRAM_CMD_TARGET_BANK1;
  }
  else if (bankx == 1)
  {
    target_bank = FMC_SDRAM_CMD_TARGET_BANK2;
  }

  Command.CommandMode = cmd;              //命令
  Command.CommandTarget = target_bank;    //目标SDRAM存储区域
  Command.AutoRefreshNumber = refresh;    //自刷新次数
  Command.ModeRegisterDefinition = regval; //要写入模式寄存器的值

  if (HAL_SDRAM_SendCommand(&hsdram1, &Command, 0xFFFF) == HAL_OK) //向SDRAM发送命令
  {
    return 0;
  }
  else
  {
    return 1;
  }
}

/* USER CODE END 0 */

int main(void)
{
  /* USER CODE BEGIN 1 */
	SCB_EnableICache();//使能I-Cache
	SCB_EnableDCache();//使能D-Cache
	SCB->CACR|=1<<2;
  char Test_Dat[10];
	uint16_t TestLen;
	uint32_t ts;
  /* USER CODE END 1 */
/* Enable the CPU Cache */

  /* Enable I-Cache---------------------------------------------------------*/
  SCB_EnableICache();

  /* Enable D-Cache---------------------------------------------------------*/
  SCB_EnableDCache();

  /* MCU Configuration--------------------------------------------------------*/

  /* Reset of all peripherals, Initializes the Flash interface and the Systick. */
  HAL_Init();

  /* Configure the system clock */
  SystemClock_Config();

/* Configure the peripherals common clocks */
  PeriphCommonClock_Config();

  /* Initialize all configured peripherals */
  MX_GPIO_Init();
  MX_DMA_Init();
  MX_FMC_Init();
  MX_USART1_UART_Init();
  MX_TIM17_Init();
  MX_SPI2_Init();
  MX_LTDC_Init();
  MX_DMA2D_Init();
  /* USER CODE BEGIN 2 */

  SDRAM_Initialization_Sequence(&hsdram1);
  UART_Init();

  /* USER CODE END 2 */

  /* Infinite loop */
  while (1)
  {

    /* USER CODE BEGIN 3 */
    LL_GPIO_ResetOutputPin(GPIOB, LL_GPIO_PIN_1 | LL_GPIO_PIN_0);
    HAL_Delay(100);
    LL_GPIO_SetOutputPin(GPIOB, LL_GPIO_PIN_1 | LL_GPIO_PIN_0);
    HAL_Delay(100);

//		*(__IO uint32_t*)(0xC30549D0) = 0x5A5AA5A5;
//		ts = *(__IO uint32_t*)(0xC30549D0);
		UART_DMA_Send(USART1, str, 20);
  }

  /* USER CODE END 3 */
}

void SystemClock_Config(void)
{
  LL_FLASH_SetLatency(LL_FLASH_LATENCY_4);
  while(LL_FLASH_GetLatency()!= LL_FLASH_LATENCY_4)
  {
  }
  LL_PWR_ConfigSupply(LL_PWR_LDO_SUPPLY);
  LL_PWR_SetRegulVoltageScaling(LL_PWR_REGU_VOLTAGE_SCALE0);
  while (LL_PWR_IsActiveFlag_VOS() == 0)
  {
  }
  LL_RCC_HSE_Enable();

   /* Wait till HSE is ready */
  while(LL_RCC_HSE_IsReady() != 1)
  {

  }
  LL_RCC_HSE_EnableCSS();
  LL_RCC_PLL_SetSource(LL_RCC_PLLSOURCE_HSE);
  LL_RCC_PLL1P_Enable();
  LL_RCC_PLL1Q_Enable();
  LL_RCC_PLL1R_Enable();
  LL_RCC_PLL1_SetVCOInputRange(LL_RCC_PLLINPUTRANGE_4_8);
  LL_RCC_PLL1_SetVCOOutputRange(LL_RCC_PLLVCORANGE_WIDE);
  LL_RCC_PLL1_SetM(5);
  LL_RCC_PLL1_SetN(192);
  LL_RCC_PLL1_SetP(2);
  LL_RCC_PLL1_SetQ(20);
  LL_RCC_PLL1_SetR(2);
  LL_RCC_PLL1_Enable();

   /* Wait till PLL is ready */
  while(LL_RCC_PLL1_IsReady() != 1)
  {
  }

   /* Intermediate AHB prescaler 2 when target frequency clock is higher than 80 MHz */
   LL_RCC_SetAHBPrescaler(LL_RCC_AHB_DIV_2);

  LL_RCC_SetSysClkSource(LL_RCC_SYS_CLKSOURCE_PLL1);

   /* Wait till System clock is ready */
  while(LL_RCC_GetSysClkSource() != LL_RCC_SYS_CLKSOURCE_STATUS_PLL1)
  {

  }
  LL_RCC_SetSysPrescaler(LL_RCC_SYSCLK_DIV_1);
  LL_RCC_SetAHBPrescaler(LL_RCC_AHB_DIV_2);
  LL_RCC_SetAPB1Prescaler(LL_RCC_APB1_DIV_2);
  LL_RCC_SetAPB2Prescaler(LL_RCC_APB2_DIV_2);
  LL_RCC_SetAPB3Prescaler(LL_RCC_APB3_DIV_2);
  LL_RCC_SetAPB4Prescaler(LL_RCC_APB4_DIV_2);
  LL_SetSystemCoreClock(480000000);

   /* Update the time base */
  if (HAL_InitTick (TICK_INT_PRIORITY) != HAL_OK)
  {
    Error_Handler();
  }
  LL_RCC_HSE_EnableCSS();
}

void PeriphCommonClock_Config(void)
{
  LL_RCC_PLL3R_Enable();
  LL_RCC_PLL3_SetVCOInputRange(LL_RCC_PLLINPUTRANGE_1_2);
  LL_RCC_PLL3_SetVCOOutputRange(LL_RCC_PLLVCORANGE_WIDE);
  LL_RCC_PLL3_SetM(25);
  LL_RCC_PLL3_SetN(240);
  LL_RCC_PLL3_SetP(2);
  LL_RCC_PLL3_SetQ(2);
  LL_RCC_PLL3_SetR(2);
  LL_RCC_PLL3_Enable();

   /* Wait till PLL is ready */
  while(LL_RCC_PLL3_IsReady() != 1)
  {
  }

}

void Error_Handler(void)
{
  __disable_irq();
  while (1)
  {
  }
}
